# ioADuCM4050 register map
Registers are 16-bit, access not given, no defined reset value unless marked. A register's access mark holds for its fields unless they carry their own. Addresses are absolute; registers are grouped by the start of their names; [hi:lo] are bit positions; {n}, {i} and the like mark numbered series.

## CRC0
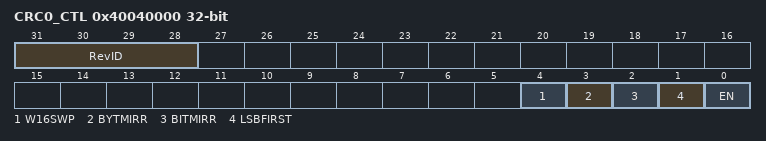
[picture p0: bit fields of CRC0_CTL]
0x40040000 CRC0_CTL 32-bit
  [31:28] RevID, [4] W16SWP, [3] BYTMIRR, [2] BITMIRR, [1] LSBFIRST, [0] EN
0x40040004 CRC0_IPDATA 32-bit
0x40040008 CRC0_RESULT 32-bit
0x4004000C CRC0_POLY 32-bit
{0x40040010+i} CRC0_IPBITS{i} 8-bit (i=0..7)
0x40040010 CRC0_IPBYTE 8-bit

## RNG0
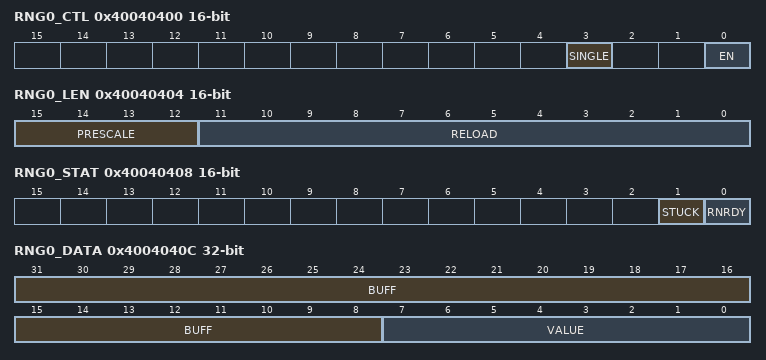
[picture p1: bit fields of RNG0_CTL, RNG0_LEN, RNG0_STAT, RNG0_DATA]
0x40040400 RNG0_CTL
  [3] SINGLE, [0] EN
0x40040404 RNG0_LEN
  [15:12] PRESCALE, [11:0] RELOAD
0x40040408 RNG0_STAT
  [1] STUCK, [0] RNRDY
0x4004040C RNG0_DATA 32-bit
  [31:8] BUFF, [7:0] VALUE
0x40040410 RNG0_OSCCNT 32-bit
  [27:0] VALUE
{0x40040414+i} RNG0_OSCDIFF{i} 8-bit (i=0..3)

## CRYPT0
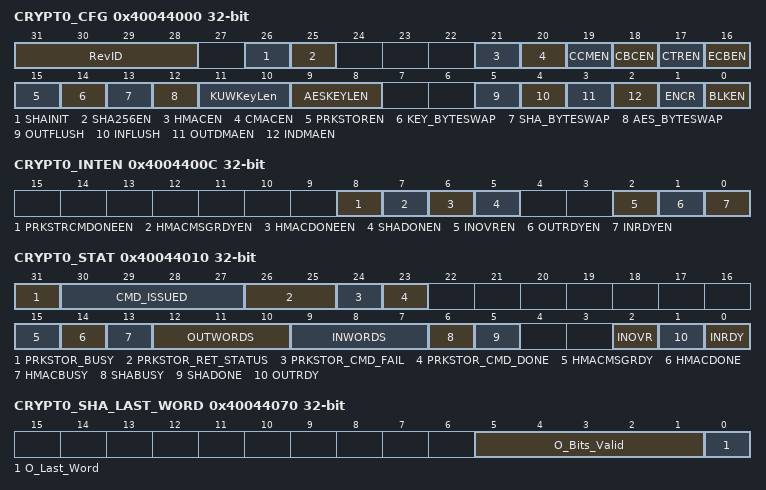
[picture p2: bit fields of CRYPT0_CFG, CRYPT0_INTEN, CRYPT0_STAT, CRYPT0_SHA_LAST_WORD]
0x40044000 CRYPT0_CFG 32-bit
  [31:28] RevID, [26] SHAINIT, [25] SHA256EN, [21] HMACEN, [20] CMACEN, [19] CCMEN, [18] CBCEN, [17] CTREN, [16] ECBEN, [15] PRKSTOREN, [14] KEY_BYTESWAP, [13] SHA_BYTESWAP, [12] AES_BYTESWAP, [11:10] KUWKeyLen, [9:8] AESKEYLEN, [5] OUTFLUSH, [4] INFLUSH, [3] OUTDMAEN, [2] INDMAEN, [1] ENCR, [0] BLKEN
0x40044004 CRYPT0_DATALEN 32-bit
  [19:0] VALUE
0x40044008 CRYPT0_PREFIXLEN 32-bit
  [15:0] VALUE
0x4004400C CRYPT0_INTEN 32-bit
  [8] PRKSTRCMDONEEN, [7] HMACMSGRDYEN, [6] HMACDONEEN, [5] SHADONEN, [2] INOVREN, [1] OUTRDYEN, [0] INRDYEN
0x40044010 CRYPT0_STAT 32-bit
  [31] PRKSTOR_BUSY, [30:27] CMD_ISSUED, [26:25] PRKSTOR_RET_STATUS, [24] PRKSTOR_CMD_FAIL, [23] PRKSTOR_CMD_DONE, [15] HMACMSGRDY, [14] HMACDONE, [13] HMACBUSY, [12:10] OUTWORDS, [9:7] INWORDS, [6] SHABUSY, [5] SHADONE, [2] INOVR, [1] OUTRDY, [0] INRDY
0x40044014 CRYPT0_INBUF 32-bit
0x40044018 CRYPT0_OUTBUF 32-bit
{0x4004401C+4i} CRYPT0_NONCE{i} 32-bit (i=0..3)
{0x4004402C+4i} CRYPT0_AESKEY{i} 32-bit (i=0..7)
0x4004404C CRYPT0_CNTRINIT 32-bit
  [19:0] VALUE
{0x40044050+4i} CRYPT0_SHAH{i} 32-bit (i=0..7)
0x40044070 CRYPT0_SHA_LAST_WORD 32-bit
  [5:1] O_Bits_Valid, [0] O_Last_Word
0x40044074 CRYPT0_CCM_NUM_VALID_BYTES 32-bit
  [3:0] NUM_VALID_BYTES
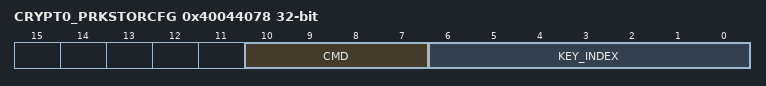
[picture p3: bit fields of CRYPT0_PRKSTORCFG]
0x40044078 CRYPT0_PRKSTORCFG 32-bit
  [10:7] CMD, [6:0] KEY_INDEX
{0x40044080+4i} CRYPT0_KUW{i} 32-bit (i=0..15)
0x400440C0 CRYPT0_KUWValStr1 32-bit
0x400440C4 CRYPT0_KUWValStr2 32-bit

## PMG0
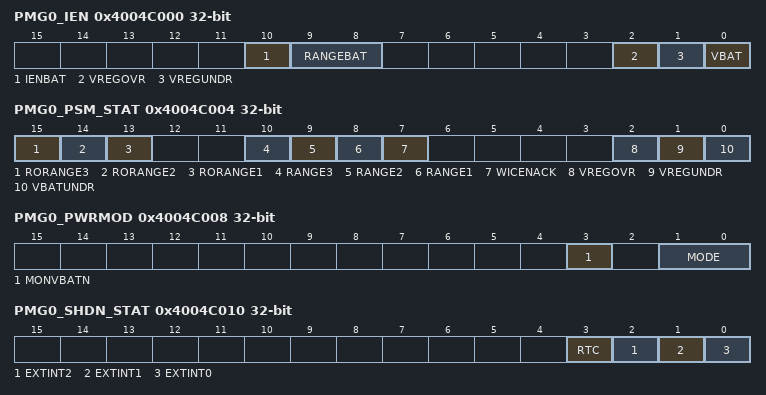
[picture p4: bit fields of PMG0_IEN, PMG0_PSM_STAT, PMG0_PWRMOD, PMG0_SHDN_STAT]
0x4004C000 PMG0_IEN 32-bit
  [10] IENBAT, [9:8] RANGEBAT, [2] VREGOVR, [1] VREGUNDR, [0] VBAT
0x4004C004 PMG0_PSM_STAT 32-bit
  [15] RORANGE3, [14] RORANGE2, [13] RORANGE1, [10] RANGE3, [9] RANGE2, [8] RANGE1, [7] WICENACK, [2] VREGOVR, [1] VREGUNDR, [0] VBATUNDR
0x4004C008 PMG0_PWRMOD 32-bit
  [3] MONVBATN, [1:0] MODE
0x4004C00C PMG0_PWRKEY 32-bit
  [15:0] VALUE
0x4004C010 PMG0_SHDN_STAT 32-bit
  [3] RTC, [2] EXTINT2, [1] EXTINT1, [0] EXTINT0
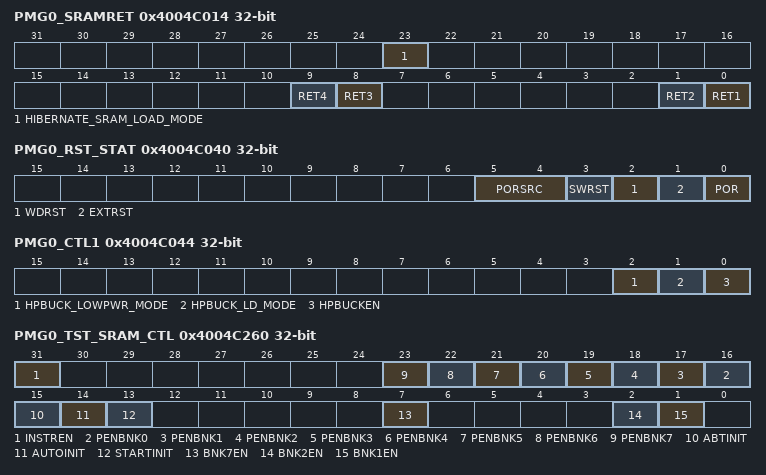
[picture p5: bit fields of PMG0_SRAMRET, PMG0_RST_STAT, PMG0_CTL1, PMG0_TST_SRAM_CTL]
0x4004C014 PMG0_SRAMRET 32-bit
  [23] HIBERNATE_SRAM_LOAD_MODE, [9] RET4, [8] RET3, [1] RET2, [0] RET1
0x4004C038 PMG0_TRIM 32-bit
  [31:29] hibernate_load_mode
0x4004C040 PMG0_RST_STAT 32-bit
  [5:4] PORSRC, [3] SWRST, [2] WDRST, [1] EXTRST, [0] POR
0x4004C044 PMG0_CTL1 32-bit
  [2] HPBUCK_LOWPWR_MODE, [1] HPBUCK_LD_MODE, [0] HPBUCKEN
0x4004C260 PMG0_TST_SRAM_CTL 32-bit
  [31] INSTREN, [n+16] PENBNK{n} (n=0..7), [15] ABTINIT, [14] AUTOINIT, [13] STARTINIT, [7] BNK7EN, [2] BNK2EN, [1] BNK1EN
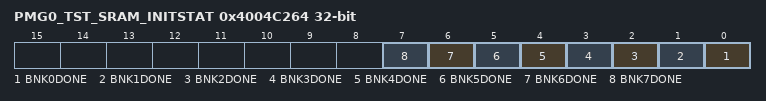
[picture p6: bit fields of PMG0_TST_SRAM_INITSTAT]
0x4004C264 PMG0_TST_SRAM_INITSTAT 32-bit
  [n] BNK{n}DONE (n=0..7)
0x4004C268 PMG0_TST_CLR_LATCH_GPIOS
0x4004C26C PMG0_TST_SCRPAD_IMG 32-bit
0x4004C270 PMG0_TST_SCRPAD_3V_RD 32-bit
0x4004C274 PMG0_TST_FAST_SHT_WAKEUP 32-bit
  [0] FAST_SHT_WAKEUP

## XINT0
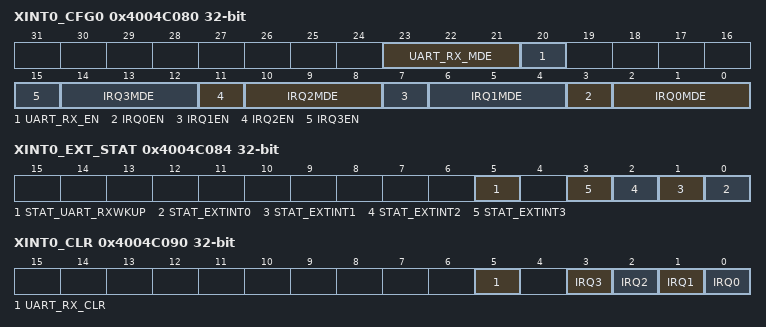
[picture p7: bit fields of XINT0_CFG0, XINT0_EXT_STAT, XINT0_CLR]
0x4004C080 XINT0_CFG0 32-bit
  [23:21] UART_RX_MDE, [20] UART_RX_EN, [4n+3] IRQ{n}EN (n=0..3), [4n+2:4n] IRQ{n}MDE (n=0..3)
0x4004C084 XINT0_EXT_STAT 32-bit
  [5] STAT_UART_RXWKUP, [n] STAT_EXTINT{n} (n=0..3)
0x4004C090 XINT0_CLR 32-bit
  [5] UART_RX_CLR, [n] IRQ{n} (n=0..3)
0x4004C094 XINT0_NMICLR 32-bit
  [0] CLR

## CLKG0
0x4004C10C CLKG0_OSC_KEY 32-bit
  [15:0] VALUE
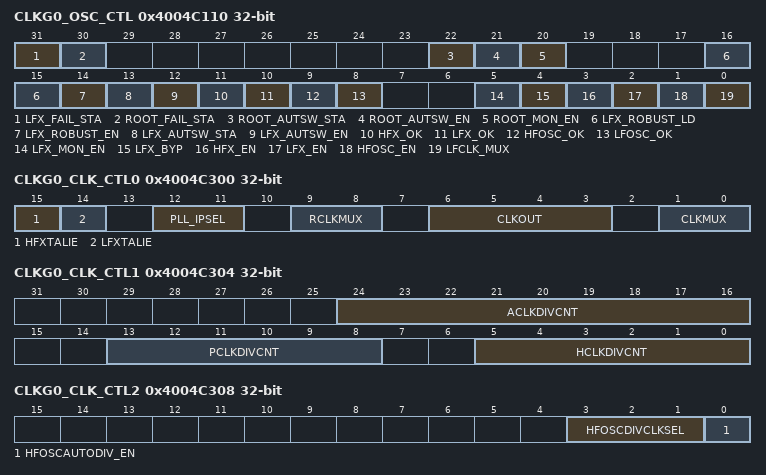
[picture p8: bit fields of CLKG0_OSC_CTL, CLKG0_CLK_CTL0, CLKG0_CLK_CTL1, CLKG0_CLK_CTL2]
0x4004C110 CLKG0_OSC_CTL 32-bit
  [31] LFX_FAIL_STA, [30] ROOT_FAIL_STA, [22] ROOT_AUTSW_STA, [21] ROOT_AUTSW_EN, [20] ROOT_MON_EN, [16:15] LFX_ROBUST_LD, [14] LFX_ROBUST_EN, [13] LFX_AUTSW_STA, [12] LFX_AUTSW_EN, [11] HFX_OK, [10] LFX_OK, [9] HFOSC_OK, [8] LFOSC_OK, [5] LFX_MON_EN, [4] LFX_BYP, [3] HFX_EN, [2] LFX_EN, [1] HFOSC_EN, [0] LFCLK_MUX
0x4004C300 CLKG0_CLK_CTL0 32-bit
  [15] HFXTALIE, [14] LFXTALIE, [12:11] PLL_IPSEL, [9:8] RCLKMUX, [6:3] CLKOUT, [1:0] CLKMUX
0x4004C304 CLKG0_CLK_CTL1 32-bit
  [24:16] ACLKDIVCNT, [13:8] PCLKDIVCNT, [5:0] HCLKDIVCNT
0x4004C308 CLKG0_CLK_CTL2 32-bit
  [3:1] HFOSCDIVCLKSEL, [0] HFOSCAUTODIV_EN
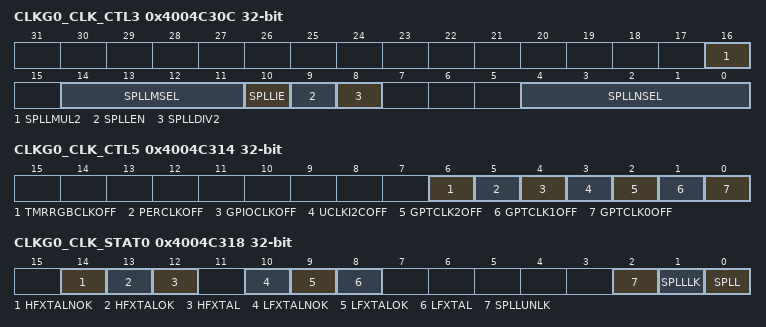
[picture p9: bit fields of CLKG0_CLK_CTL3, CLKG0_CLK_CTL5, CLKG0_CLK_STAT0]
0x4004C30C CLKG0_CLK_CTL3 32-bit
  [16] SPLLMUL2, [14:11] SPLLMSEL, [10] SPLLIE, [9] SPLLEN, [8] SPLLDIV2, [4:0] SPLLNSEL
0x4004C314 CLKG0_CLK_CTL5 32-bit
  [6] TMRRGBCLKOFF, [5] PERCLKOFF, [4] GPIOCLKOFF, [3] UCLKI2COFF, [2] GPTCLK2OFF, [1] GPTCLK1OFF, [0] GPTCLK0OFF
0x4004C318 CLKG0_CLK_STAT0 32-bit
  [14] HFXTALNOK, [13] HFXTALOK, [12] HFXTAL, [10] LFXTALNOK, [9] LFXTALOK, [8] LFXTAL, [2] SPLLUNLK, [1] SPLLLK, [0] SPLL

## BUSM0
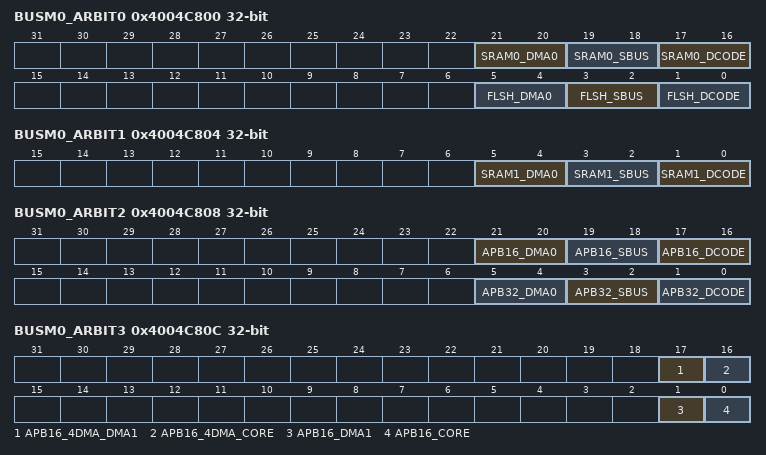
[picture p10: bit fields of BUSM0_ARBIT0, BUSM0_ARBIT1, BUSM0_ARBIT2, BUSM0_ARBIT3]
0x4004C800 BUSM0_ARBIT0 32-bit
  [21:20] SRAM0_DMA0, [19:18] SRAM0_SBUS, [17:16] SRAM0_DCODE, [5:4] FLSH_DMA0, [3:2] FLSH_SBUS, [1:0] FLSH_DCODE
0x4004C804 BUSM0_ARBIT1 32-bit
  [5:4] SRAM1_DMA0, [3:2] SRAM1_SBUS, [1:0] SRAM1_DCODE
0x4004C808 BUSM0_ARBIT2 32-bit
  [21:20] APB16_DMA0, [19:18] APB16_SBUS, [17:16] APB16_DCODE, [5:4] APB32_DMA0, [3:2] APB32_SBUS, [1:0] APB32_DCODE
0x4004C80C BUSM0_ARBIT3 32-bit
  [17] APB16_4DMA_DMA1, [16] APB16_4DMA_CORE, [1] APB16_DMA1, [0] APB16_CORE
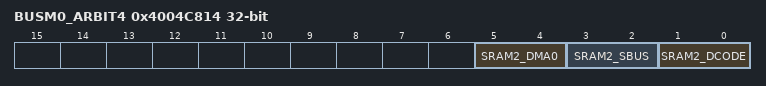
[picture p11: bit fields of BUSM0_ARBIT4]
0x4004C814 BUSM0_ARBIT4 32-bit
  [5:4] SRAM2_DMA0, [3:2] SRAM2_SBUS, [1:0] SRAM2_DCODE

## NVIC0
0xE000E004 NVIC0_INTNUM 32-bit
0xE000E010 NVIC0_STKSTA 32-bit
0xE000E014 NVIC0_STKLD 32-bit
0xE000E018 NVIC0_STKVAL 32-bit
0xE000E01C NVIC0_STKCAL 32-bit
{0xE000E100+4i} NVIC0_INTSETE{i} 32-bit (i=0..2)
{0xE000E180+4i} NVIC0_INTCLRE{i} 32-bit (i=0..2)
{0xE000E200+4i} NVIC0_INTSETP{i} 32-bit (i=0..2)
{0xE000E280+4i} NVIC0_INTCLRP{i} 32-bit (i=0..2)
{0xE000E300+4i} NVIC0_INTACT{i} 32-bit (i=0..2)
{0xE000E400+4i} NVIC0_INTPRI{i} 32-bit (i=0..17)
0xE000ED00 NVIC0_INTCPID 32-bit
0xE000ED04 NVIC0_INTSTA 32-bit
0xE000ED08 NVIC0_INTVEC 32-bit
0xE000ED0C NVIC0_INTAIRC 32-bit
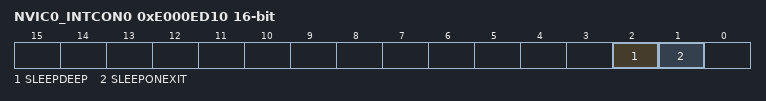
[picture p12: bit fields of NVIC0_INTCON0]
0xE000ED10 NVIC0_INTCON0
  [2] SLEEPDEEP, [1] SLEEPONEXIT
0xE000ED14 NVIC0_INTCON1 32-bit
0xE000ED18 NVIC0_INTSHPRIO0 32-bit
0xE000ED1C NVIC0_INTSHPRIO1 32-bit
0xE000ED20 NVIC0_INTSHPRIO3 32-bit
0xE000ED24 NVIC0_INTSHCSR 32-bit
0xE000ED28 NVIC0_INTCFSR 32-bit
0xE000ED2C NVIC0_INTHFSR 32-bit
0xE000ED30 NVIC0_INTDFSR 32-bit
0xE000ED34 NVIC0_INTMMAR 32-bit
0xE000ED38 NVIC0_INTBFAR 32-bit
0xE000ED3C NVIC0_INTAFSR 32-bit
0xE000ED40 NVIC0_INTPFR0 32-bit
0xE000ED44 NVIC0_INTPFR1 32-bit
0xE000ED48 NVIC0_INTDFR0 32-bit
0xE000ED4C NVIC0_INTAFR0 32-bit
{0xE000ED50+4i} NVIC0_INTMMFR{i} 32-bit (i=0..3)
{0xE000ED60+4i} NVIC0_INTISAR{i} 32-bit (i=0..4)
0xE000EF00 NVIC0_INTTRGI 32-bit
{0xE000EFC0+4i} NVIC0_INTPID{i} 32-bit (i=4..7)
{0xE000EFE0+4i} NVIC0_INTPID{i} 32-bit (i=0..3)
{0xE000EFF0+4i} NVIC0_INTCID{i} 32-bit (i=0..3)
